# tle984x register map
Vendor: Infineon; File version: 1.9.5
CPU: CM0 r2p1, little endian, no MPU, no FPU, 2 interrupt priority bits
Registers are 32-bit, read-write, reset 0x0 unless marked. A register's access mark holds for its fields unless they carry their own. Offsets are from the block's base; [hi:lo] are bit positions; {n}, {i} and the like mark numbered series; 'fields as' and 'values as' point back to an identical list.

## ADC1 — 10-bit Analog Digital Converter (ADC1) registers
Base 0x40004000
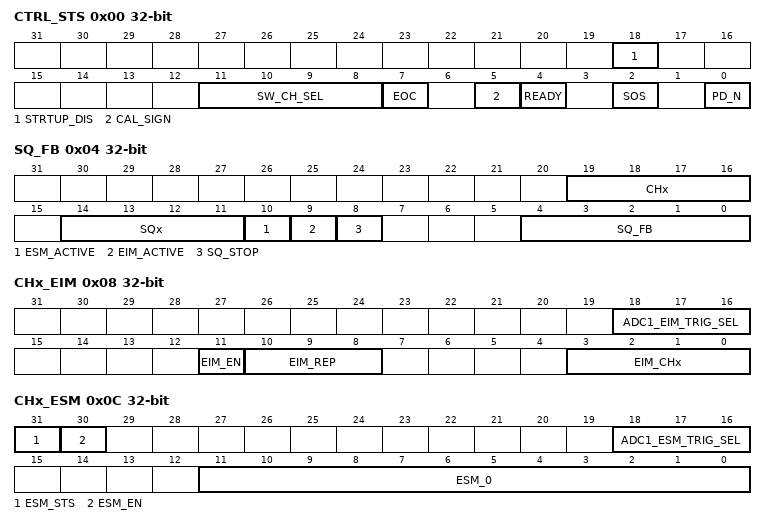
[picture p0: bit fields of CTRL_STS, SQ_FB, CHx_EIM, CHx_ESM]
0x00 CTRL_STS — ADC1 control and status register
  [18] STRTUP_DIS — DPP1 startup disable
    0=START_UP_ENABLE (DPP1 start-up enabled); 1=START_UP_DISABLE (DPP1 start-up disable)
  [11:8] SW_CH_SEL — Channel for software mode
    {v}=CH{v}_EN (Channel {v} enable) (v=0..12)
  [7] EOC ro — ADC1 End of Conversion (software mode)
    0=PENDING (Conversion still running); 1=FINISHED (Conversion has finished)
  [5] CAL_SIGN ro — Output of comparator to steer gain/offset calibration
  [4] READY ro — HVADC ready bit
    0=NOT_READY (Module in power-down or in init phase); 1=READY (Set automatically 5 ADC clock cycles after module is enabled)
  [2] SOS — ADC1 Start of sampling/conversion (software mode)
    0=DISABLE (No conversion is started); 1=ENABLE (Conversion is started)
  [0] PD_N — ADC1 Power-down signal
    0=POWER_DOWN (ADC1 is powered down); 1=ACTIVE (ADC1 is switched on)
0x04 SQ_FB ro (reset mask 0xFF0000F0) — Sequencer feedback register
  [19:16] CHx — Current ADC1 channel
    {v}=CH{v} (Channel {v} enable) (v=0..11)
  [14:11] SQx — Current active ADC1 sequence
    {v}=SQ{v} (Sequence {v} enable) (v=0..11)
  [10] ESM_ACTIVE — ADC1 ESM active
    0=NOT_ACTIVE (ESM not active); 1=ACTIVE (ESM active)
  [9] EIM_ACTIVE — ADC1 EIM active
    0=NOT_ACTIVE (EIM not active); 1=ACTIVE (EIM active)
  [8] SQ_STOP — ADC1 sequencer stop signal for DPP
    0=DPP_RUNNING (Postprocessing sequencer in running mode); 1=DPP_STOPPED (Postprocessing sequencer stopped/software mode entered)
  [4:0] SQ_FB — Current sequence that caused software mode
    {v}=SQ{v} (Sequence {v} enable) (v=0..11); 12=ESM; 14=SUSPEND_SW (Software mode per flag); 15=SUSPEND_DSG (Debug suspend mode)
0x08 CHx_EIM — Channel setting bits for exceptional interrupt measurement register
  [18:16] ADC1_EIM_TRIG_SEL — Trigger selection for exceptional interrupt measurement (EIM)
    0=NONE; 1=COUT63; 2=GPT12_T6OUT; 3=GPT12_T3OUT; 4=T2 (t2_adc_trigger); 5=T21 (t21_adc_trigger)
  [11] EIM_EN — Exceptional interrupt measurement (EIM) Trigger Event enable
    0=DISABLE (Start of EIM disabled); 1=ENABLE (Start of EIM enabled)
  [10:8] EIM_REP — Repeat count for exceptional interrupt measurement (EIM)
    0=1 measurement; 1=2 measurements; 2=4 measurements; 3=8 measurements; 4=16 measurements; 5=32 measurements; 6=64 measurements; 7=128 measurements
  [3:0] EIM_CHx — Channel set for exceptional interrupt measurement (EIM)
    {v}=CH{v} (Channel {v} enable) (v=0..11)
0x0C CHx_ESM — Channel setting bits for exceptional sequence measurement register
  [31] ESM_STS — Exceptional sequence measurement is finished
    0=NOT_ACTIVE (Exceptional Sequence Measurement not done); 1=DONE (Exceptional Sequence Measurement done)
  [30] ESM_EN — Enable for Exceptional Sequence Measurement Trigger Event
    0=DISABLE (Start of ESM disabled); 1=ENABLE (Start of ESM enabled)
  [18:16] ADC1_ESM_TRIG_SEL — Trigger selection for exceptional interrupt measurement (ESM)
    values as CHx_EIM.ADC1_EIM_TRIG_SEL
  [11:0] ESM_0 — Channel sequence for exceptional sequence measurement (ESM)
    1=CH0_EN (Channel 0 enable); 2=CH1_EN (Channel 1 enable); 4=CH2_EN (Channel 2 enable); 8=CH3_EN (Channel 3 enable); 16=CH4_EN (Channel 4 enable); 32=CH5_EN (Channel 5 enable); 64=CH6_EN (Channel 6 enable); 128=CH7_EN (Channel 7 enable); 0x100=CH8_EN (Channel 8 enable); 0x200=CH9_EN (Channel 9 enable); 0x400=CH10_EN (Channel 10 enable); 0x800=CH11_EN (Channel 11 enable)
0x10 MAX_TIME — Maximum time for software mode register
  [7:0] MAX_TIME — Maximum Time in software mode
    0=MIN (Software mode is immediately left); 255=MAX (Software mode is active for 12.75 us)
0x14 CTRL2 — Measurement unit 1 control 2 register
  [11:0] CAL_EN — Calibration enable for channels 0 to 11
    1=CH0_EN (Channel 0 calibration enable); 2=CH1_EN (Channel 1 calibration enable); 4=CH2_EN (Channel 2 calibration enable); 8=CH3_EN (Channel 3 calibration enable); 16=CH4_EN (Channel 4 calibration enable); 32=CH5_EN (Channel 5 calibration enable); 64=CH6_EN (Channel 6 calibration enable); 128=CH7_EN (Channel 7 calibration enable); 0x100=CH8_EN (Channel 8 calibration enable); 0x200=CH9_EN (Channel 9 calibration enable); 0x400=CH10_EN (Channel 10 calibration enable); 0x800=CH11_EN (Channel 11 calibration enable)
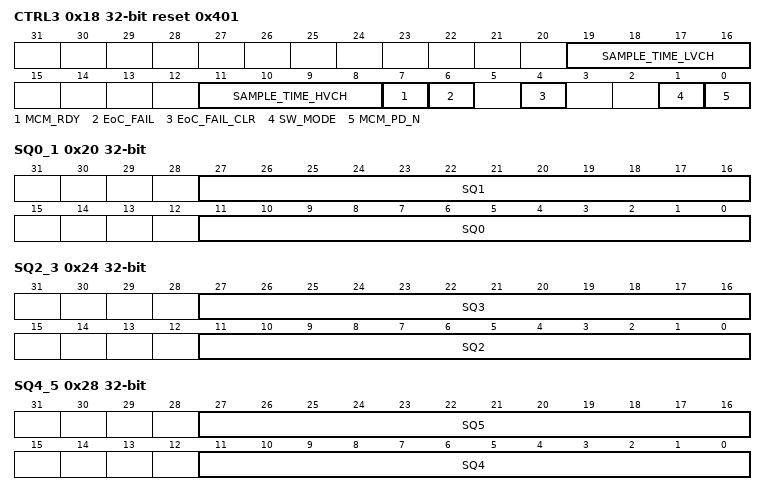
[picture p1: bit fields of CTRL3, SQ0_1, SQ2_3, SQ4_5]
0x18 CTRL3 reset 0x401 — Measurement unit 1 control 3 register
  [19:16] SAMPLE_TIME_LVCH — Sample time of ADC1
    0=MICLK4 (4 ADC1_CLK clock periods (default)); 1=MICLK6 (6 ADC1_CLK clock periods); 2=MICLK8 (8 ADC1_CLK clock periods); 3=MICLK10 (10 ADC1_CLK clock periods); 4=MICLK12 (12 ADC1_CLK clock periods); 5=MICLK14 (14 ADC1_CLK clock periods); 6=MICLK16 (16 ADC1_CLK clock periods); 7=MICLK18 (18 ADC1_CLK clock periods); 8=MICLK20 (20 ADC1_CLK clock periods); 9=MICLK22 (22 ADC1_CLK clock periods); {v}=MICLK12_{v-9} (12 ADC1_CLK clock periods) (v=10..15)
  [11:8] SAMPLE_TIME_HVCH — Sample time of ADC1
    0=MICLK4 (4 ADC1_CLK clock periods); 1=MICLK6 (6 ADC1_CLK clock periods); 2=MICLK8 (8 ADC1_CLK clock periods); 3=MICLK10 (10 ADC1_CLK clock periods); 4=MICLK12 (12 ADC1_CLK clock periods (default)); 5=MICLK14 (14 ADC1_CLK clock periods); 6=MICLK16 (16 ADC1_CLK clock periods); 7=MICLK18 (18 ADC1_CLK clock periods); 8=MICLK20 (20 ADC1_CLK clock periods); 9=MICLK22 (22 ADC1_CLK clock periods); {v}=MICLK4_{v-9} (4 ADC1_CLK clock periods) (v=10..15)
  [7] MCM_RDY ro — Ready signal for MCM (Measurement core module) after power on or reset
    0=MCM_NOT_READY (Measurement core module in start-up phase); 1=MCM_READY (Measurement core module start-up phase finished)
  [6] EoC_FAIL ro — Fail of ADC end of conversion signal
    0=ADC_EoC_AVAILABLE (End of conversion signal was sent properly by ADC); 1=ADC_EoC_NOT_AVAILABLE (End of conversion signal was not sent properly by ADC)
  [4] EoC_FAIL_CLR wo — Fail of ADC end of conversion signal clear
    0=ADC_EoC_FAIL_NOT_CLEAR (No clear of EoC_FAIL flag); 1=ADC_EoC_FAIL_CLEAR (Clear of EoC_FAIL flag)
  [1] SW_MODE — Software mode enable
    0=SOFTWARE_MODE_DISABLE (Sequencer running); 1=SOFTWARE_MODE_ENABLED (Sequencer stopped)
  [0] MCM_PD_N — Power-down signal for MCM
    0=MCM_DISABLED (Measurement core module disabled); 1=MCM_ENABLED (Measurement core module enabled)
0x1C CTRL5 — Measurement unit 1 control 5 register
  [11:0] FILT_OUT_SEL_11_0 — Output filter selection for channels 0 to 11
    0=UNF (ADC1 unfiltered data can be monitored in the corresponding FILT_OUTx registers); 1=CH0 (Channel 0 IIR data enabled for FILT_OUT0 register); 2=CH1 (Channel 1 IIR data enabled for FILT_OUT1 register); 4=CH2 (Channel 2 IIR data enabled for FILT_OUT2 register); 8=CH3 (Channel 3 IIR data enabled for FILT_OUT3 register); 16=CH4 (Channel 4 IIR data enabled for FILT_OUT4 register); 32=CH5 (Channel 5 IIR data enabled for FILT_OUT5 register); 64=CH6 (Channel 6 IIR data enabled for FILT_OUT6 register); 128=CH7 (Channel 7 IIR data enabled for FILT_OUT7 register); 0x100=CH8 (Channel 8 IIR data enabled for FILT_OUT8 register); 0x200=CH9 (Channel 9 IIR data enabled for FILT_OUT9 register); 0x400=CH10 (Channel 10 IIR data enabled for FILT_OUT10 register); 0x800=CH11 (Channel 11 IIR data enabled for FILT_OUT11 register); 0xFFF=CH11_0 (For channels 11-0 IIR data is enabled for FILT_OUTx registers)
0x20 SQ0_1 — Measurement unit 1 channel enable bits for cycle 0-1 register
  [27:16] SQ1 — Sequence 1 channel enable
    values as CHx_ESM.ESM_0
  [11:0] SQ0 — Sequence 0 channel enable
    values as CHx_ESM.ESM_0
0x24 SQ2_3 — Measurement unit 1 channel enable bits for cycle 2-3 register
  [27:16] SQ3 — Sequence 3 channel enable
    values as CHx_ESM.ESM_0
  [11:0] SQ2 — Sequence 2 channel enable
    values as CHx_ESM.ESM_0
0x28 SQ4_5 — Measurement unit 1 channel enable bits for cycle 4-5 register
  [27:16] SQ5 — Sequence 5 channel enable
    values as CHx_ESM.ESM_0
  [11:0] SQ4 — Sequence 4 channel enable
    values as CHx_ESM.ESM_0
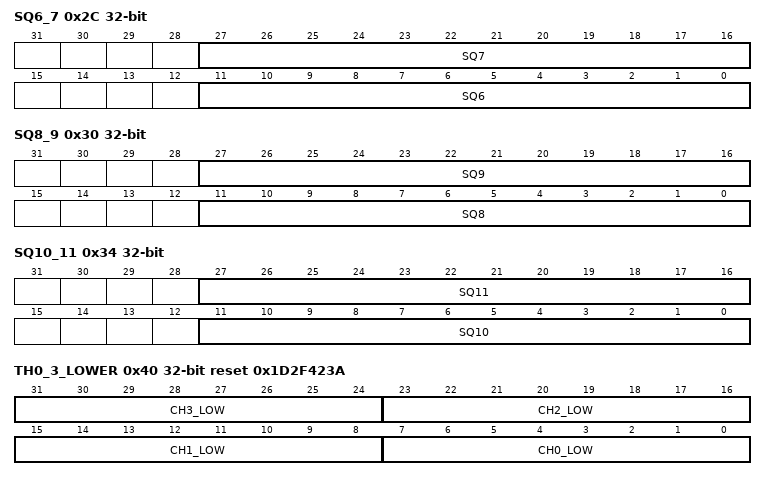
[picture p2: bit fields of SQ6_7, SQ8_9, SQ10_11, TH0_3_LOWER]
0x2C SQ6_7 — Measurement unit 1 channel enable bits for cycle 6-7 register
  [27:16] SQ7 — Sequence 7 channel enable
    values as CHx_ESM.ESM_0
  [11:0] SQ6 — Sequence 6 channel enable
    values as CHx_ESM.ESM_0
0x30 SQ8_9 — Measurement unit 1 channel enable bits for cycle 8-9 register
  [27:16] SQ9 — Sequence 9 channel enable
    1=CH0_EN (Channel 0 enable); 2=CH1_EN (Channel 1 enable); 4=CH2_EN (Channel 2 enable); 8=CH3_EN (Channel 3 enable); 16=CH4_EN (Channel 4 enable); 32=CH5_EN (Channel 5 enable); 64=CH6_EN (Channel 6 enable); 128=CH7_EN (Channel 7 enable); 0x100=CH8_EN (Channel 8 enable); 0x200=CH9_EN (Channel 9 enable); 0x400=CH10_EN (Channel 10 enable); 0x7E8=CH11_EN (Channel 11 enable)
  [11:0] SQ8 — Sequence 8 channel enable
    values as CHx_ESM.ESM_0
0x34 SQ10_11 — Measurement unit 1 channel enable bits for cycle 10-11 register
  [27:16] SQ11 — Sequence 11 channel enable
    values as CHx_ESM.ESM_0
  [11:0] SQ10 — Sequence 10 channel enable
    values as CHx_ESM.ESM_0
0x38 CTRL4 — Measurement unit 1 control 4 register
  [3:0] MAX_CALTIME — Maximum ADC calibration time
    0=Sequence; {v}=Sequences (v=1..15)
0x40 TH0_3_LOWER reset 0x1D2F423A — Lower comparator trigger level channel 0-3
  [all] fields
    0=MIN (Min. threshold value); 255=MAX (Max. threshold value)
  [8n+7:8n] CH{n}_LOW (n=0..3) — Channel {n} lower trigger level
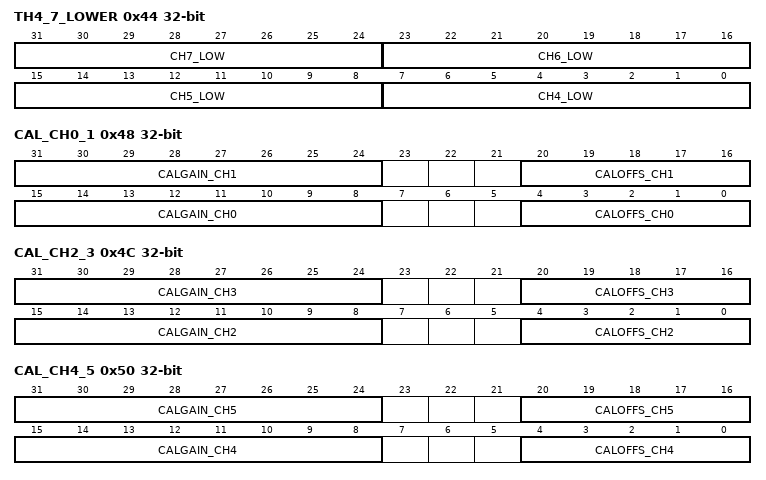
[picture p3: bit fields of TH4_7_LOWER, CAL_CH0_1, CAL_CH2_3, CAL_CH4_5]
0x44 TH4_7_LOWER — Lower comparator trigger level channel 4-7
  [all] fields
    0=MIN (Min. threshold value); 255=MAX (Max. threshold value)
  [8n-25:8n-32] CH{n}_LOW (n=4..7) — Channel {n} lower trigger level
0x48 CAL_CH0_1 — Calibration for channel 0 and 1 register
  [31:24] CALGAIN_CH1 — Gain calibration for channel 1
  [20:16] CALOFFS_CH1 — Offset calibration for channel 1
  [15:8] CALGAIN_CH0 — Gain calibration for channel 0
  [4:0] CALOFFS_CH0 — Offset calibration for channel 0
0x4C CAL_CH2_3 — Calibration for channel 2 and 3 register
  [31:24] CALGAIN_CH3 — Gain calibration for channel 3
  [20:16] CALOFFS_CH3 — Offset calibration for channel 3
  [15:8] CALGAIN_CH2 — Gain calibration for channel 2
  [4:0] CALOFFS_CH2 — Offset calibration for channel 2
0x50 CAL_CH4_5 — Calibration for channel 4 and 5 register
  [31:24] CALGAIN_CH5 — Gain calibration for channel 5
  [20:16] CALOFFS_CH5 — Offset calibration for channel 5
  [15:8] CALGAIN_CH4 — Gain calibration for channel 4
  [4:0] CALOFFS_CH4 — Offset calibration for channel 4
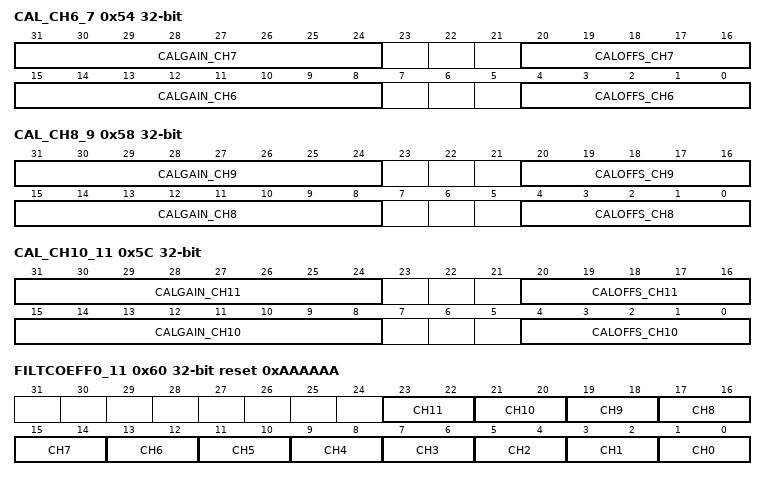
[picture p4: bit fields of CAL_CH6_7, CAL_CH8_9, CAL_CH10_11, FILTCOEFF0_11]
0x54 CAL_CH6_7 — Calibration for channel 6 and 7 register
  [31:24] CALGAIN_CH7 — Gain calibration for channel 7
  [20:16] CALOFFS_CH7 — Offset calibration for channel 7
  [15:8] CALGAIN_CH6 — Gain calibration for channel 6
  [4:0] CALOFFS_CH6 — Offset calibration for channel 6
0x58 CAL_CH8_9 — Calibration for channel 8 and 9 register
  [31:24] CALGAIN_CH9 — Gain calibration for channel 9
  [20:16] CALOFFS_CH9 — Offset calibration for channel 9
  [15:8] CALGAIN_CH8 — Gain calibration for channel 8
  [4:0] CALOFFS_CH8 — Offset calibration for channel 8
0x5C CAL_CH10_11 — Calibration for channel 10 and 11 register
  [31:24] CALGAIN_CH11 — Gain calibration for channel 11
  [20:16] CALOFFS_CH11 — Offset calibration for channel 11
  [15:8] CALGAIN_CH10 — Gain calibration for channel 10
  [4:0] CALOFFS_CH10 — Offset calibration for channel 10
0x60 FILTCOEFF0_11 reset 0xAAAAAA — Filter coefficients measurement unit channel 0-11 register
  [all] fields
    0=1_2 (1/2 weight of current sample); 1=1_4 (1/4 weight of current sample); 2=1_8 (1/8 weight of current sample); 3=1/16 weight of current sample
  [2n+1:2n] CH{n} (n=7..11) — Filter coefficients ADC channel {n}
  [13:12] CH6 — Filter Coefficients ADC channel 6
  [2n+1:2n] CH{n} (n=0..5) — Filter coefficients ADC channel {n}
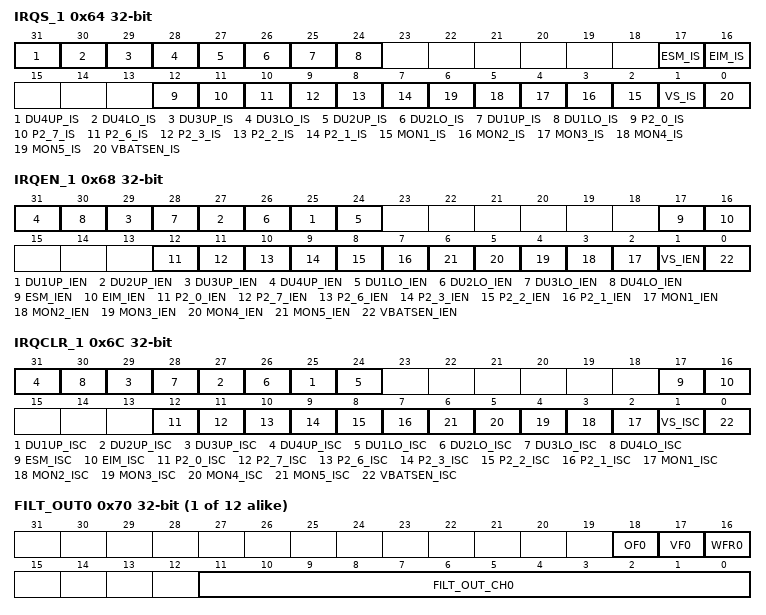
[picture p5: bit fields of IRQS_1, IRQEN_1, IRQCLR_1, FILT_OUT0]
0x64 IRQS_1 — ADC1 interrupt status 1 register
  [31] DU4UP_IS — ADC1 differential unit 4 (DU4) upper channel interrupt dtatus
    0=INACTIVE (No DU upper channel interrupt has occurred); 1=ACTIVE (DU upper channel interrupt has occurred)
  [30] DU4LO_IS — ADC1 differential unit 4 (DU4) lower channel interrupt status
    0=INACTIVE (No DU lower channel interrupt has occurred); 1=ACTIVE (DU lower channel interrupt has occurred)
  [29] DU3UP_IS — ADC1 differential unit 3 (DU3) upper channel interrupt status
    values as DU4UP_IS
  [28] DU3LO_IS — ADC1 differential unit 3 (DU3) lower Channel interrupt status
    values as DU4LO_IS
  [27] DU2UP_IS — ADC1 differential unit 2 (DU2) upper channel interrupt status
    values as DU4UP_IS
  [26] DU2LO_IS — ADC1 differential unit 2 (DU2) lower channel interrupt status
    values as DU4LO_IS
  [25] DU1UP_IS — ADC1 differential unit 1 (DU1) upper channel interrupt status
    0=INACTIVE (No DU upper Channel Interrupt has occurred); 1=ACTIVE (DU upper Channel Interrupt has occurred)
  [24] DU1LO_IS — ADC1 Differential Unit 1 (DU1) lower channel interrupt status
    0=INACTIVE (No DU lower channel Interrupt has occurred); 1=ACTIVE (DU lower channel interrupt has occurred)
  [17] ESM_IS — Exceptional sequence measurement (ESM) status
    0=INACTIVE (No ESM has occurred); 1=ACTIVE (ESM occurred)
  [16] EIM_IS — Exceptional interrupt measurement (EIM) status
    0=INACTIVE (No EIM occurred); 1=ACTIVE (EIM occurred)
  [12] P2_0_IS — ADC1 channel 12 interrupt status
    0=INACTIVE (No channel 12 interrupt has occurred); 1=ACTIVE (Channel 12 interrupt has occurred)
  [11] P2_7_IS — ADC1 channel 11 interrupt status
    0=INACTIVE (No channel 11 interrupt has occurred); 1=ACTIVE (Channel 11 interrupt has occurred)
  [10] P2_6_IS — ADC1 channel 10 interrupt status
    0=INACTIVE (No channel 10 interrupt has occurred); 1=ACTIVE (Channel 10 interrupt has occurred)
  [9] P2_3_IS — ADC1 channel 9 interrupt status
    0=INACTIVE (No channel 9 interrupt has occurred); 1=ACTIVE (Channel 9 interrupt has occurred)
  [8] P2_2_IS — ADC1 channel 8 interrupt status
    0=INACTIVE (No channel 8 interrupt has occurred); 1=ACTIVE (Channel 8 interrupt has occurred)
  [7] P2_1_IS — ADC1 channel 7 interrupt status
    0=INACTIVE (No channel 7 interrupt has occurred); 1=ACTIVE (Channel 7 interrupt has occurred)
  [n+1] MON{n}_IS (n=1..5) — ADC1 channel {n+1} interrupt status
    0=INACTIVE (No channel {n+1} interrupt has occurred); 1=ACTIVE (Channel {n+1} interrupt has occurred)
  [1] VS_IS — ADC1 channel 0 interrupt status
    0=INACTIVE (No channel 0 interrupt has occurred); 1=ACTIVE (Channel 0 interrupt has occurred)
  [0] VBATSEN_IS — ADC1 channel 1 interrupt status
    0=INACTIVE (No channel 1 interrupt has occurred); 1=ACTIVE (Channel 1 interrupt has occurred)
0x68 IRQEN_1 — ADC1 interrupt enable 1 register
  [all] fields
    0=DISABLED (Interrupt disabled); 1=ENABLED (Interrupt enabled)
  [2n+23] DU{n}UP_IEN (n=1..4) — Differential unit {n} upper interrupt enable
  [2n+22] DU{n}LO_IEN (n=1..4) — Differential unit {n} lower interrupt enable
  [17] ESM_IEN — Exceptional sequence measurement (ESM) interrupt enable
  [16] EIM_IEN — Exceptional interrupt measurement (EIM) interrupt enable
  [12] P2_0_IEN — ADC1 Port 2.0 interrupt enable
  [11] P2_7_IEN — ADC1 Port 2.7 interrupt enable
  [10] P2_6_IEN — ADC1 Port 2.6 interrupt enable
  [9] P2_3_IEN — ADC1 Port 2.3 interrupt enable
  [8] P2_2_IEN — ADC1 Port 2.2 interrupt enable
  [7] P2_1_IEN — ADC1 Port 2.1 interrupt enable
  [n+1] MON{n}_IEN (n=1..5) — ADC1 MON {n} interrupt enable
  [1] VS_IEN — ADC1 VS interrupt enable
  [0] VBATSEN_IEN — ADC1 VBAT_SENSE interrupt enable
0x6C IRQCLR_1 — ADC1 interrupt status clear 1 register
  [2n+23] DU{n}UP_ISC wo (n=1..4) — Differential unit {n} lower interrupt status clear
    0=INACTIVE (Interrupt status is not cleared); 1=ACTIVE (Interrupt status is cleared)
  [2n+22] DU{n}LO_ISC wo (n=1..4) — Differential unit {n} lower interrupt status clear
    values as DU1UP_ISC
  [17] ESM_ISC wo — Exceptional sequence measurement (ESM) status clear
    0=INACTIVE (No ESM has cleared); 1=ACTIVE (ESM cleared)
  [16] EIM_ISC wo — Exceptional interrupt measurement (EIM) status clear
    0=INACTIVE (No EIM cleared); 1=ACTIVE (EIM cleared)
  [12] P2_0_ISC wo — ADC1 Port 2.0 interrupt status clear
    values as DU1UP_ISC
  [11] P2_7_ISC wo — ADC1 Port 2.7 interrupt status clear
    values as DU1UP_ISC
  [10] P2_6_ISC wo — ADC1 Port 2.6 interrupt status clear
    values as DU1UP_ISC
  [9] P2_3_ISC wo — ADC1 Port 2.3 interrupt status clear
    values as DU1UP_ISC
  [8] P2_2_ISC wo — ADC1 Port 2.2 interrupt status clear
    values as DU1UP_ISC
  [7] P2_1_ISC wo — ADC1 Port 2.1 interrupt status clear
    values as DU1UP_ISC
  [n+1] MON{n}_ISC wo (n=1..5) — ADC1 MON {n} interrupt status clear
    values as DU1UP_ISC
  [1] VS_ISC wo — ADC1 VS interrupt status clear
    values as DU1UP_ISC
  [0] VBATSEN_ISC wo — ADC1 VBAT_SENSE interrupt status clear
    values as DU1UP_ISC
{0x70+4i} FILT_OUT{i} (reset mask 0xFFFFF000) (i=0..11) — ADC1 or filter output channel {i} register
  [18] OF{i} ro — Overrun flag
    0=NO_OVERRUN (Result register not overwritten); 1=OVERRUN (Result register overwritten)
  [17] VF{i} ro — Valid flag
    0=NOT_VALID (No new valid data available); 1=VALID (Result register contains valid data and has not yet been read)
  [16] WFR{i} — Wait for read mode
    0=DISABLE (Overwrite mode); 1=ENABLE (Wait for read mode enabled)
  [11:0] FILT_OUT_CH{i} ro — ADC or filter output value channel {i}
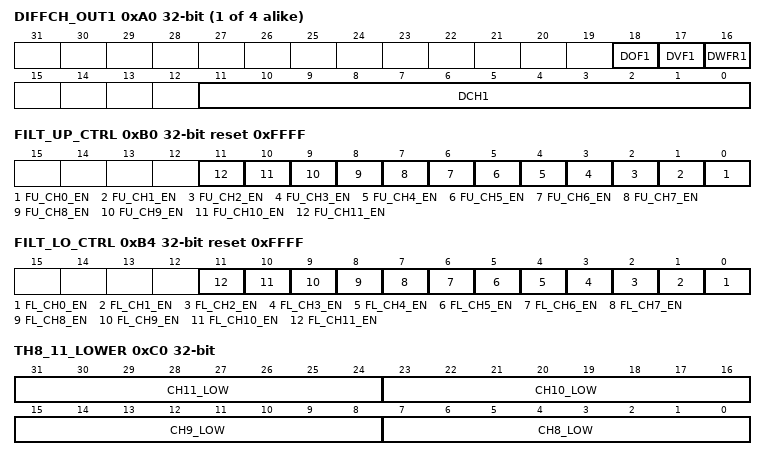
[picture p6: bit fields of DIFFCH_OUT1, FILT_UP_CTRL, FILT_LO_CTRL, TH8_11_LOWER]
{0x9C+4i} DIFFCH_OUT{i} (reset mask 0xFFFFF000) (i=1..4) — ADC1 differential channel output {i} register
  [18] DOF{i} ro — Overrun flag
    values as FILT_OUT0.OF{i}
  [17] DVF{i} ro — Valid flag
    values as FILT_OUT0.VF{i}
  [16] DWFR{i} — Wait for read mode
    values as FILT_OUT0.WFR{i}
  [11:0] DCH{i} ro — ADC differential output value {i}
0xB0 FILT_UP_CTRL reset 0xFFFF — Upper threshold filter enable
  [all] fields
    0=DISABLE; 1=ENABLE
  [n] FU_CH{n}_EN (n=0..11) — Upper threshold IIR filter enable channel {n}
0xB4 FILT_LO_CTRL reset 0xFFFF — Lower Threshold filter enable
  [all] fields
    0=DISABLE; 1=ENABLE
  [n] FL_CH{n}_EN (n=0..11) — Lower threshold IIR filter enable channel {n}
0xC0 TH8_11_LOWER — Lower comparator trigger level channel 8-11
  [all] fields
    0=MIN (Min. threshold value); 255=MAX (Max. threshold value)
  [8n-57:8n-64] CH{n}_LOW (n=8..11) — Channel {n} lower trigger level
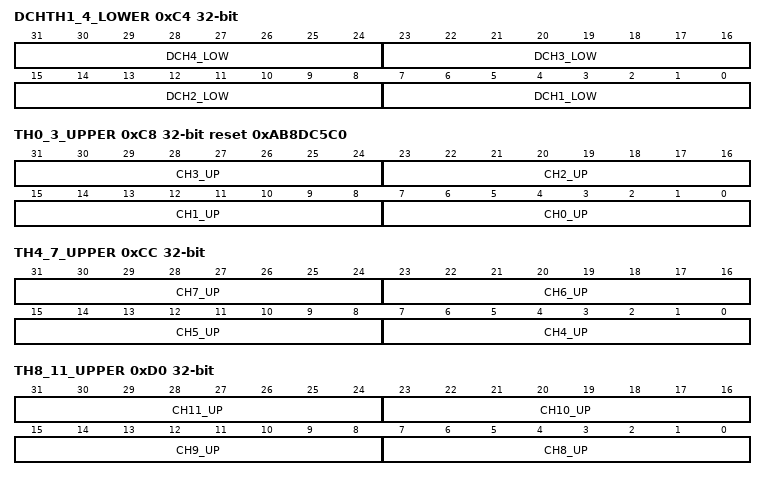
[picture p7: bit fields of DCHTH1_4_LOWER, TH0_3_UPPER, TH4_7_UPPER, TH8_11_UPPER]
0xC4 DCHTH1_4_LOWER — Lower comparator trigger level differential channel 1-4 register
  [all] fields
    0=MIN (Min. threshold value); 255=MAX (Max. threshold value)
  [8n-1:8n-8] DCH{n}_LOW (n=1..4) — Differential channel {n} lower trigger level
0xC8 TH0_3_UPPER reset 0xAB8DC5C0 — Upper comparator trigger level channel 0-3 register
  [all] fields
    0=MIN (Min. threshold value = 0); 255=MAX (Max. threshold value = 255)
  [8n+7:8n] CH{n}_UP (n=0..3) — Channel {n} upper trigger level
0xCC TH4_7_UPPER — Upper comparator trigger level channel 4-7 register
  [all] fields
    values as the fields of TH0_3_UPPER
  [8n-25:8n-32] CH{n}_UP (n=4..7) — Channel {n} upper trigger level
0xD0 TH8_11_UPPER — Upper comparator trigger level channel 8-11 register
  [all] fields
    values as the fields of TH0_3_UPPER
  [8n-57:8n-64] CH{n}_UP (n=8..11) — Channel {n} upper trigger level
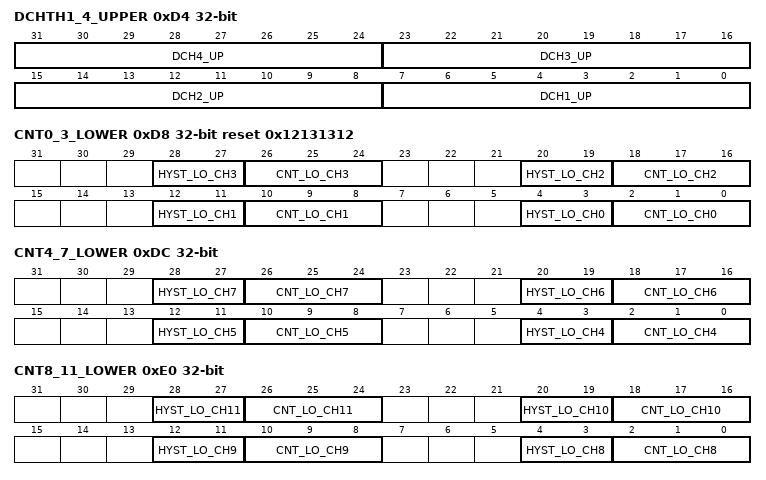
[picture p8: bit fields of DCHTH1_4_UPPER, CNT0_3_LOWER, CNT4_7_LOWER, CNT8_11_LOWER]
0xD4 DCHTH1_4_UPPER — Upper comparator trigger level differential channel 1-4 register
  [all] fields
    values as the fields of TH0_3_UPPER
  [8n-1:8n-8] DCH{n}_UP (n=1..4) — Differential channel {n} upper trigger level
0xD8 CNT0_3_LOWER reset 0x12131312 — Lower counter trigger level channel 0-3 register
  [8n+4:8n+3] HYST_LO_CH{n} (n=0..3) — Channel {n} lower hysteresis
    0=HYSTOFF (Hysteresis switched off); 1=HYST4 (Hysteresis = 4); 2=HYST8 (Hysteresis = 8); 3=HYST16 (Hysteresis = 16)
  [8n+2:8n] CNT_LO_CH{n} (n=0..3) — Lower timer trigger threshold channel {n}
    0=1 measurement; 1=2 measurements; 2=4 measurements; 3=8 measurements; 4=16 measurements; 5=32 measurements; 6=63 measurements; 7=63 measurements
0xDC CNT4_7_LOWER — Lower counter trigger level channel 4-7 register
  [8n-28:8n-29] HYST_LO_CH{n} (n=4..7) — Channel {n} lower hysteresis
    values as CNT0_3_LOWER.HYST_LO_CH0
  [8n-30:8n-32] CNT_LO_CH{n} (n=4..7) — Lower timer trigger threshold channel {n}
    values as CNT0_3_LOWER.CNT_LO_CH0
0xE0 CNT8_11_LOWER — Lower counter trigger level channel 8-11 register
  [8n-60:8n-61] HYST_LO_CH{n} (n=8..11) — Channel {n} lower hysteresis
    values as CNT0_3_LOWER.HYST_LO_CH0
  [8n-62:8n-64] CNT_LO_CH{n} (n=8..11) — Lower timer trigger threshold channel {n}
    values as CNT0_3_LOWER.CNT_LO_CH0
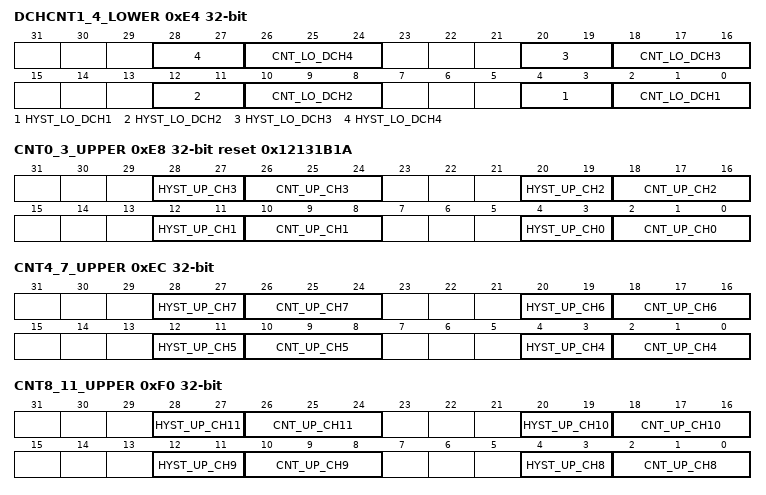
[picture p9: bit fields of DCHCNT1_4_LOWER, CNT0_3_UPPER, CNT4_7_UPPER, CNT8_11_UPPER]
0xE4 DCHCNT1_4_LOWER — Lower counter trigger level differential channel 1-4 register
  [8n-4:8n-5] HYST_LO_DCH{n} (n=1..4) — Differential Channel {n} lower hysteresis
    values as CNT0_3_LOWER.HYST_LO_CH0
  [8n-6:8n-8] CNT_LO_DCH{n} (n=1..4) — Lower timer trigger threshold differential channel {n}
    values as CNT0_3_LOWER.CNT_LO_CH0
0xE8 CNT0_3_UPPER reset 0x12131B1A — Upper counter trigger level channel 0-3 register
  [8n+4:8n+3] HYST_UP_CH{n} (n=0..3) — Channel {n} upper hysteresis
    values as CNT0_3_LOWER.HYST_LO_CH0
  [8n+2:8n] CNT_UP_CH{n} (n=0..3) — Upper timer trigger threshold channel {n}
    values as CNT0_3_LOWER.CNT_LO_CH0
0xEC CNT4_7_UPPER — Upper counter trigger level channel 4-7 register
  [8n-28:8n-29] HYST_UP_CH{n} (n=4..7) — Channel {n} upper hysteresis
    values as CNT0_3_LOWER.HYST_LO_CH0
  [8n-30:8n-32] CNT_UP_CH{n} (n=4..7) — Upper timer trigger threshold channel {n}
    values as CNT0_3_LOWER.CNT_LO_CH0
0xF0 CNT8_11_UPPER — Upper counter trigger level channel 8-11 register
  [8n-60:8n-61] HYST_UP_CH{n} (n=8..11) — Channel {n} upper hysteresis
    values as CNT0_3_LOWER.HYST_LO_CH0
  [8n-62:8n-64] CNT_UP_CH{n} (n=8..11) — Upper timer trigger threshold channel {n}
    values as CNT0_3_LOWER.CNT_LO_CH0
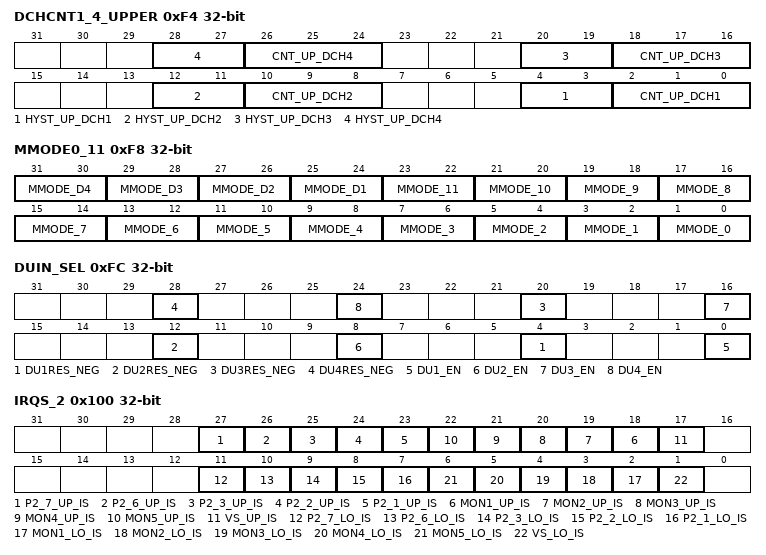
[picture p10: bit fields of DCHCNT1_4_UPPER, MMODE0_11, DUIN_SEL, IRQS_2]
0xF4 DCHCNT1_4_UPPER — Upper counter trigger level differential channel 1-4 register
  [8n-4:8n-5] HYST_UP_DCH{n} (n=1..4) — Differential channel {n} upper hysteresis
    values as CNT0_3_LOWER.HYST_LO_CH0
  [8n-6:8n-8] CNT_UP_DCH{n} (n=1..4) — Upper timer trigger threshold differential channel {n}
    0=1 measurement; 1=2 measurements; 2=4 measurements; 3=8 measurements; {v}=15 measurements (v=4..7)
0xF8 MMODE0_11 — Overvoltage measurement mode of channel 0-11 register
  [all] fields
    0=MMODE0 (Upper & lower voltage/limit measurement); 1=MMODEUV (Undervoltage/-limit measurement); 2=MMODEOV (Overvoltage/-limit measurement)
  [2n+23:2n+22] MMODE_D{n} (n=1..4) — Measurement mode differential channel {n}
  [2n+1:2n] MMODE_{n} (n=0..11) — Measurement mode channel {n}
0xFC DUIN_SEL — Measurement unit 1 - Differential unit input selection register
  [8n-4] DU{n}RES_NEG ro (n=1..4) — Differential unit {n} result negative
    0=DU{n}_RESULT_POSITIVE (Differential unit {n} result positive after calculation); 1=DU{n}_RESULT_NEGATIVE (Differential unit {n} result negative after calculation)
  [8n-8] DU{n}_EN (n=1..4) — Differential unit {n} enable
    0=DU{n}_DISABLE (Differential unit {n} is disabled); 1=DU{n}_ENABLE (Differential unit {n} is enabled)
0x100 IRQS_2 — ADC1 interrupt status 2 register
  [all] fields
    0=INACTIVE (No interrupt has occurred); 1=ACTIVE (Interrupt has occurred)
  [27] P2_7_UP_IS — ADC1 port 2.7 upper threshold interrupt status
  [26] P2_6_UP_IS — ADC1 port 2.6 upper threshold interrupt status
  [25] P2_3_UP_IS — ADC1 port 2.3 upper threshold interrupt status
  [24] P2_2_UP_IS — ADC1 port 2.2 upper threshold interrupt status
  [23] P2_1_UP_IS — ADC1 port 2.1 upper threshold interrupt status
  [n+17] MON{n}_UP_IS (n=1..5) — ADC1 MON {n} upper threshold interrupt status
  [17] VS_UP_IS — ADC1 VS upper threshold interrupt status
  [11] P2_7_LO_IS — ADC1 port 2.7 lower threshold interrupt status
  [10] P2_6_LO_IS — ADC1 port 2.6 lower threshold interrupt status
  [9] P2_3_LO_IS — ADC1 port 2.3 lower threshold interrupt status
  [8] P2_2_LO_IS — ADC1 port 2.2 lower threshold interrupt status
  [7] P2_1_LO_IS — ADC1 port 2.1 lower threshold interrupt status
  [n+1] MON{n}_LO_IS (n=1..5) — ADC1 MON {n} lower threshold interrupt status
  [1] VS_LO_IS — ADC1 VS lower threshold interrupt status
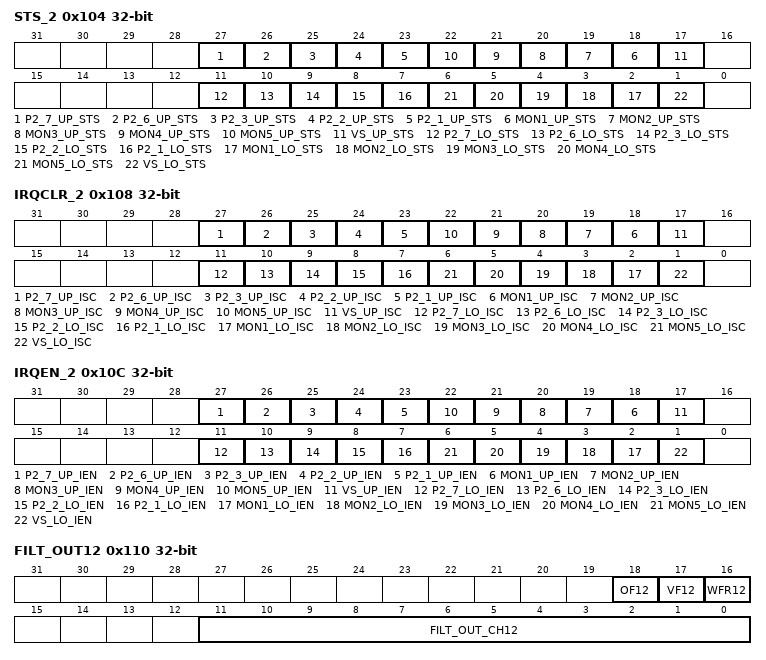
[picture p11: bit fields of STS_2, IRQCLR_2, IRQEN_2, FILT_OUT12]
0x104 STS_2 ro — ADC1 status 2 register
  [all] fields
    0=BELOW_LIMIT (Status below upper threshold); 1=ABOVE_LIMIT (Upper threshold exceeded)
  [27] P2_7_UP_STS — ADC1 port 2.7 upper threshold status
  [26] P2_6_UP_STS — ADC1 port 2.6 upper threshold status
  [25] P2_3_UP_STS — ADC1 port 2.3 upper threshold status
  [24] P2_2_UP_STS — ADC1 port 2.2 upper threshold Status
  [23] P2_1_UP_STS — ADC1 port 2.1 upper threshold Status
  [n+17] MON{n}_UP_STS (n=1..5) — ADC1 MON {n} upper threshold Status
  [17] VS_UP_STS — ADC1 VS upper threshold Status
  [11] P2_7_LO_STS — ADC1 port 2.7 lower threshold status
  [10] P2_6_LO_STS — ADC1 port 2.6 lower threshold status
  [9] P2_3_LO_STS — ADC1 port 2.3 lower threshold status
  [8] P2_2_LO_STS — ADC1 port 2.2 lower threshold status
  [7] P2_1_LO_STS — ADC1 port 2.1 lower threshold status
  [n+1] MON{n}_LO_STS (n=1..5) — ADC1 MON {n} lower threshold status
  [1] VS_LO_STS — ADC1 VS lower threshold status
0x108 IRQCLR_2 — ADC1 interrupt status clear 2 register
  [all] fields
    values as IRQCLR_1.DU1UP_ISC
  [27] P2_7_UP_ISC wo — ADC1 port 2.7 upper threshold interrupt status clear
  [26] P2_6_UP_ISC wo — ADC1 port 2.6 upper threshold interrupt status clear
  [25] P2_3_UP_ISC wo — ADC1 port 2.3 upper threshold interrupt status clear
  [24] P2_2_UP_ISC wo — ADC1 port 2.2 upper threshold interrupt status clear
  [23] P2_1_UP_ISC wo — ADC1 port 2.1 upper threshold interrupt status clear
  [n+17] MON{n}_UP_ISC wo (n=1..5) — ADC1 MON {n} upper threshold interrupt status clear
  [17] VS_UP_ISC wo — ADC1 VS upper threshold interrupt status clear
  [11] P2_7_LO_ISC wo — ADC1 port 2.7 lower threshold interrupt status clear
  [10] P2_6_LO_ISC wo — ADC1 port 2.6 lower threshold interrupt status clear
  [9] P2_3_LO_ISC wo — ADC1 port 2.3 lower threshold interrupt status clear
  [8] P2_2_LO_ISC wo — ADC1 port 2.2 lower threshold interrupt status clear
  [7] P2_1_LO_ISC wo — ADC1 port 2.1 lower threshold interrupt status clear
  [n+1] MON{n}_LO_ISC wo (n=1..5) — ADC1 MON {n} lower threshold interrupt status clear
  [1] VS_LO_ISC wo — ADC1 VS lower threshold interrupt status clear
0x10C IRQEN_2 — ADC1 interrupt enable 2 register
  [all] fields
    values as the fields of IRQEN_1
  [27] P2_7_UP_IEN — ADC1 port 2.7 upper threshold interrupt enable
  [26] P2_6_UP_IEN — ADC1 port 2.6 upper threshold interrupt enable
  [25] P2_3_UP_IEN — ADC1 port 2.3 upper threshold interrupt enable
  [24] P2_2_UP_IEN — ADC1 port 2.2 upper threshold interrupt enable
  [23] P2_1_UP_IEN — ADC1 port 2.1 upper threshold interrupt enable
  [n+17] MON{n}_UP_IEN (n=1..5) — ADC1 MON {n} upper threshold interrupt enable
  [17] VS_UP_IEN — ADC1 VS upper threshold interrupt enable
  [11] P2_7_LO_IEN — ADC1 port 2.7 lower threshold interrupt enable
  [10] P2_6_LO_IEN — ADC1 port 2.6 lower threshold interrupt enable
  [9] P2_3_LO_IEN — ADC1 port 2.3 lower threshold interrupt enable
  [8] P2_2_LO_IEN — ADC1 port 2.2 lower threshold interrupt enable
  [7] P2_1_LO_IEN — ADC1 port 2.1 lower threshold interrupt enable
  [n+1] MON{n}_LO_IEN (n=1..5) — ADC1 MON {n} lower threshold interrupt enable
  [1] VS_LO_IEN — ADC1 VS lower threshold interrupt enable
0x110 FILT_OUT12 (reset mask 0xFFFFF000) — ADC1 or filter output channel 12 register
  [18] OF12 ro — Overrun flag
    values as FILT_OUT0.OF{i}
  [17] VF12 ro — Valid flag
    values as FILT_OUT0.VF{i}
  [16] WFR12 — Wait for read mode
    values as FILT_OUT0.WFR{i}
  [11:0] FILT_OUT_CH12 ro — ADC or filter output value channel 12
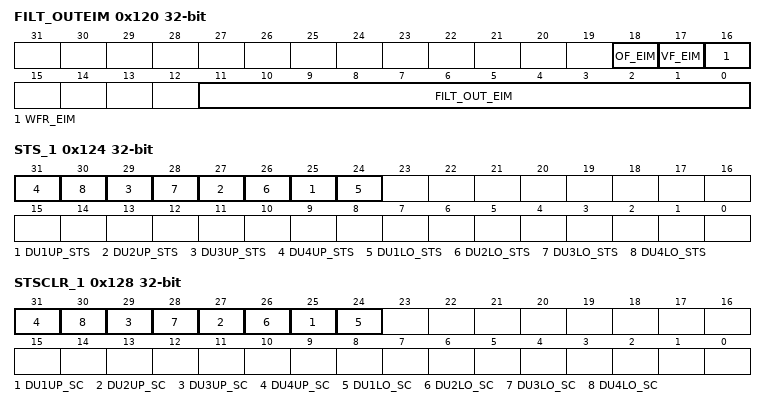
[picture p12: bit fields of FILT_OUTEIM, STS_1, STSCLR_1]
0x120 FILT_OUTEIM (reset mask 0xFFFFF000) — ADC1 or filter output of EIM register
  [18] OF_EIM ro — Overrun flag
    values as FILT_OUT0.OF{i}
  [17] VF_EIM ro — Valid flag
    values as FILT_OUT0.VF{i}
  [16] WFR_EIM — Wait for read mode
    values as FILT_OUT0.WFR{i}
  [11:0] FILT_OUT_EIM ro — ADC or filter output value for last EIM measurement
0x124 STS_1 — ADC1 status 1 register
  [2n+23] DU{n}UP_STS (n=1..4) — ADC1 differential unit {n} (DU{n}) upper channel status
    0=INACTIVE (No DU upper channel status has occurred); 1=ACTIVE (DU upper channel status has occurred)
  [2n+22] DU{n}LO_STS (n=1..4) — ADC1 differential unit {n} (DU{n}) lower channel status
    0=INACTIVE (No DU lower channel status has occurred); 1=ACTIVE (DU lower channel status has occurred)
0x128 STSCLR_1 — ADC1 status clear 1 register
  [2n+23] DU{n}UP_SC wo (n=1..4) — ADC1 differential unit {n} (DU{n}) upper channel status clear
    values as STS_1.DU1UP_STS
  [2n+22] DU{n}LO_SC wo (n=1..4) — ADC1 differential unit {n} (DU{n}) lower channel status clear
    values as STS_1.DU1LO_STS

## Notices in the file
Copyright (c) 2022 Infineon Technologies AG
Permission is hereby granted, free of charge, to any person or organization
obtaining a copy of the software and accompanying documentation covered by
this license (the "Software") to use, reproduce, display, distribute,
execute, and transmit the Software, and to prepare derivative works of the
Software, and to permit third-parties to whom the Software is furnished to
do so, all subject to the following:
The copyright notices in the Software and this entire statement, including
the above license grant, this restriction and the following disclaimer,
must be included in all copies of the Software, in whole or in part, and
all derivative works of the Software, unless such copies or derivative
works are solely in the form of machine-executable object code generated by
a source language processor.
THE SOFTWARE IS PROVIDED "AS IS", WITHOUT WARRANTY OF ANY KIND, EXPRESS OR IMPLIED, INCLUDING BUT
NOT LIMITED TO THE WARRANTIES OF MERCHANTABILITY, FITNESS FOR A PARTICULAR PURPOSE, TITLE AND
NON-INFRINGEMENT. IN NO EVENT SHALL THE COPYRIGHT HOLDERS OR ANYONE DISTRIBUTING THE SOFTWARE BE
LIABLE FOR ANY DAMAGES OR OTHER LIABILITY, WHETHER IN CONTRACT, TORT OR OTHERWISE, ARISING FROM,
OUT OF OR IN CONNECTION WITH THE SOFTWARE OR THE USE OR OTHER DEALINGS IN THE SOFTWARE.
